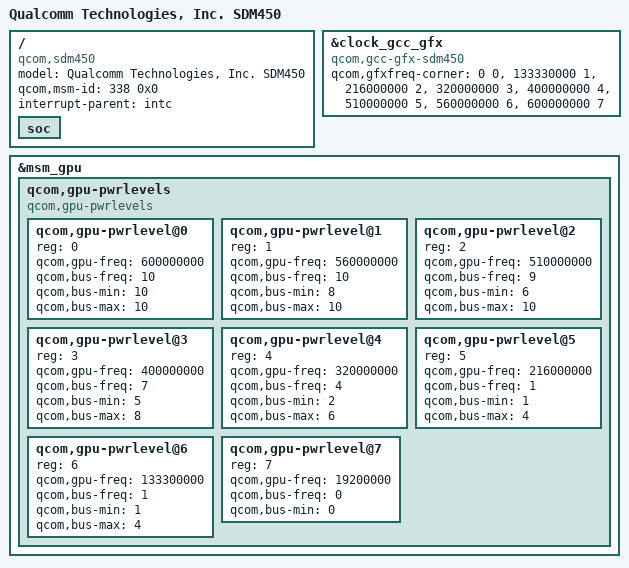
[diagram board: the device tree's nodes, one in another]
/ {
	model = "Qualcomm Technologies, Inc. SDM450";
	compatible = "qcom,sdm450";
	qcom,msm-id = <338 0x0>;
	interrupt-parent = <&intc>;

	soc: soc { };
};

&clock_gcc_gfx {
	compatible = "qcom,gcc-gfx-sdm450";
	qcom,gfxfreq-corner =
		<         0   0 >,
		< 133330000   1 >,  /* Min SVS   */
		< 216000000   2 >,  /* Low SVS   */
		< 320000000   3 >,  /* SVS       */
		< 400000000   4 >,  /* SVS Plus  */
		< 510000000   5 >,  /* NOM       */
		< 560000000   6 >,  /* Nom Plus  */
		< 600000000   7 >;  /* Turbo     */
};

&msm_gpu {
	/delete-node/ qcom,gpu-pwrlevels;

	qcom,gpu-pwrlevels {
		#address-cells = <1>;
		#size-cells = <0>;
		compatible = "qcom,gpu-pwrlevels";

		qcom,gpu-pwrlevel@0 { /* TURBO */
			reg = <0>;
			qcom,gpu-freq = <600000000>;
			qcom,bus-freq = <10>;
			qcom,bus-min = <10>;
			qcom,bus-max = <10>;
		};

		qcom,gpu-pwrlevel@1 { /* NOM+ */
			reg = <1>;
			qcom,gpu-freq = <560000000>;
			qcom,bus-freq = <10>;
			qcom,bus-min = <8>;
			qcom,bus-max = <10>;
		};

		qcom,gpu-pwrlevel@2 { /* NOM */
			reg = <2>;
			qcom,gpu-freq = <510000000>;
			qcom,bus-freq = <9>;
			qcom,bus-min = <6>;
			qcom,bus-max = <10>;
		};

		qcom,gpu-pwrlevel@3 { /* SVS+ */
			reg = <3>;
			qcom,gpu-freq = <400000000>;
			qcom,bus-freq = <7>;
			qcom,bus-min = <5>;
			qcom,bus-max = <8>;
		};

		qcom,gpu-pwrlevel@4 { /* SVS */
			reg = <4>;
			qcom,gpu-freq = <320000000>;
			qcom,bus-freq = <4>;
			qcom,bus-min = <2>;
			qcom,bus-max = <6>;
		};

		qcom,gpu-pwrlevel@5 { /* Low SVS */
			reg = <5>;
			qcom,gpu-freq = <216000000>;
			qcom,bus-freq = <1>;
			qcom,bus-min = <1>;
			qcom,bus-max = <4>;
		};

		qcom,gpu-pwrlevel@6 { /* Min SVS */
			reg = <6>;
			qcom,gpu-freq = <133300000>;
			qcom,bus-freq = <1>;
			qcom,bus-min = <1>;
			qcom,bus-max = <4>;
		};

		qcom,gpu-pwrlevel@7 { /* XO */
			reg = <7>;
			qcom,gpu-freq = <19200000>;
			qcom,bus-freq = <0>;
			qcom,bus-min = <0>;
		};
	};
};
